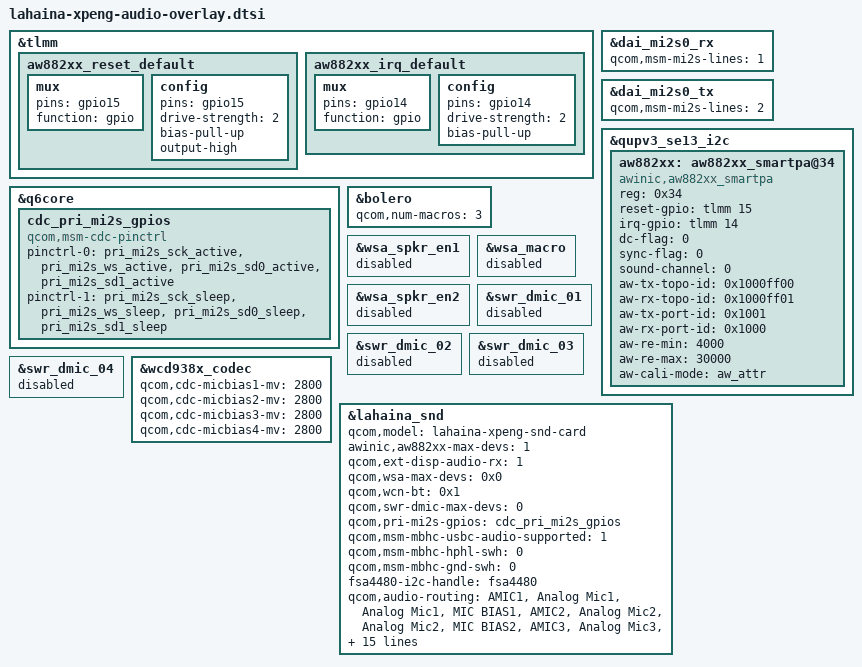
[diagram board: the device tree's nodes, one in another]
/* Copyright (c) 2019, The Linux Foundation. All rights reserved.
 *
 * This program is free software; you can redistribute it and/or modify
 * it under the terms of the GNU General Public License version 2 and
 * only version 2 as published by the Free Software Foundation.
 *
 * This program is distributed in the hope that it will be useful,
 * but WITHOUT ANY WARRANTY; without even the implied warranty of
 * MERCHANTABILITY or FITNESS FOR A PARTICULAR PURPOSE.  See the
 * GNU General Public License for more details.
 */

#include "lahaina-audio-overlay.dtsi"

&tlmm {
	aw882xx_reset_default: aw882xx_reset_default {
		mux {
			pins = "gpio15";
			function = "gpio";
		};
		config {
			pins = "gpio15";
			drive-strength = <2>; /* 2 MA */
			bias-pull-up;
			output-high;
		};
	};

	aw882xx_irq_default: aw882xx_irq_default {
		mux {
			pins = "gpio14";
			function = "gpio";
		};
		config {
			pins = "gpio14";
			drive-strength = <2>; /* 2 MA */
			bias-pull-up;
		};
	};
};

&dai_mi2s0_rx {
	status = "ok";
	qcom,msm-mi2s-lines = <1>;
};

&dai_mi2s0_tx {
        status = "ok";
        qcom,msm-mi2s-lines = <2>;
};

&q6core {
        cdc_pri_mi2s_gpios: cdc_pri_mi2s_gpios {
                compatible = "qcom,msm-cdc-pinctrl";
                pinctrl-names = "aud_active", "aud_sleep";
                pinctrl-0 = <&pri_mi2s_sck_active &pri_mi2s_ws_active
                                &pri_mi2s_sd0_active &pri_mi2s_sd1_active>;
                pinctrl-1 = <&pri_mi2s_sck_sleep &pri_mi2s_ws_sleep
                                &pri_mi2s_sd0_sleep &pri_mi2s_sd1_sleep>;
                #gpio-cells = <0>;
        };
};

&qupv3_se13_i2c {
	status = "ok";
	aw882xx: aw882xx_smartpa@34 {
		status = "okay";
		compatible = "awinic,aw882xx_smartpa";
		reg = <0x34>;
		reset-gpio = <&tlmm 15 0>;
		irq-gpio = <&tlmm 14 0x2008>;
		dc-flag = <0>;
		sync-flag = <0>;
		sound-channel = <0>;
		aw-tx-topo-id = <0x1000ff00>;
		aw-rx-topo-id = <0x1000ff01>;
		aw-tx-port-id = <0x1001>;
		aw-rx-port-id = <0x1000>;
		aw-re-min = <4000>;
		aw-re-max= <30000>;
		aw-cali-mode = "aw_attr";
	};
};

&bolero {
	status = "ok";
        qcom,num-macros = <3>;
};

&wsa_spkr_en1 {
        status = "disabled";
};

&wsa_spkr_en2 {
        status = "disabled";
};

&wsa_macro {
        status = "disabled";
};

&swr_dmic_01 {
        status = "disabled";
};

&swr_dmic_02 {
        status = "disabled";
};

&swr_dmic_03 {
        status = "disabled";
};

&swr_dmic_04 {
        status = "disabled";
};

/* Modify headset's BIAS voltage to 2.8V */
&wcd938x_codec {
	qcom,cdc-micbias1-mv = <2800>;
	qcom,cdc-micbias2-mv = <2800>;
	qcom,cdc-micbias3-mv = <2800>;
	qcom,cdc-micbias4-mv = <2800>;
};

&lahaina_snd {
	qcom,model = "lahaina-xpeng-snd-card";
	awinic,aw882xx-max-devs = <1>;
	qcom,ext-disp-audio-rx = <1>;
	qcom,wsa-max-devs = <0x0>;
        qcom,wcn-bt = <0x1>;
        qcom,swr-dmic-max-devs = <0>;
	qcom,pri-mi2s-gpios = <&cdc_pri_mi2s_gpios>;
        qcom,msm-mbhc-usbc-audio-supported = <1>;
        qcom,msm-mbhc-hphl-swh = <0>;
        qcom,msm-mbhc-gnd-swh = <0>;

	fsa4480-i2c-handle = <&fsa4480>;

	/*  Primary   AMIC3  PRI_MIC_BIAS  MIC_BIAS3
		Secondary AMIC1  SEC_MIC_BIAS  MIC_BIAS1
		Third     AMIC4  SEC_MIC_BIAS  MIC_BIAS1
		HS        AMIC2  HS_MIC_BIAS   MIC_BIAS2
	*/
	qcom,audio-routing =
		"AMIC1", "Analog Mic1",
		"Analog Mic1", "MIC BIAS1",
		"AMIC2", "Analog Mic2",
		"Analog Mic2", "MIC BIAS2",
		"AMIC3", "Analog Mic3",
		"Analog Mic3", "MIC BIAS3",
		"AMIC4", "Analog Mic4",
		"Analog Mic4", "MIC BIAS4",
		"IN1_HPHL", "HPHL_OUT",
		"IN2_HPHR", "HPHR_OUT",
		"IN3_AUX", "AUX_OUT",
		"RX_TX DEC0_INP", "TX DEC0 MUX",
		"RX_TX DEC1_INP", "TX DEC1 MUX",
		"RX_TX DEC2_INP", "TX DEC2 MUX",
		"RX_TX DEC3_INP", "TX DEC3 MUX",
		"TX SWR_INPUT", "WCD_TX_OUTPUT",
		"VA SWR_INPUT", "VA_SWR_CLK",
		"VA SWR_INPUT", "WCD_TX_OUTPUT",
		"VA_AIF1 CAP", "VA_SWR_CLK",
		"VA_AIF2 CAP", "VA_SWR_CLK",
		"VA_AIF3 CAP", "VA_SWR_CLK";
	asoc-codec  = <&stub_codec>, <&bolero>,
		<&wcd938x_codec>, <&aw882xx>, <&ext_disp_audio_codec>, <&swr_haptics>;
	asoc-codec-names = "msm-stub-codec.1", "bolero_codec",
		"wcd938x_codec", "aw882xx_codec", "msm-ext-disp-audio-codec-rx", "swr-haptics";

};
